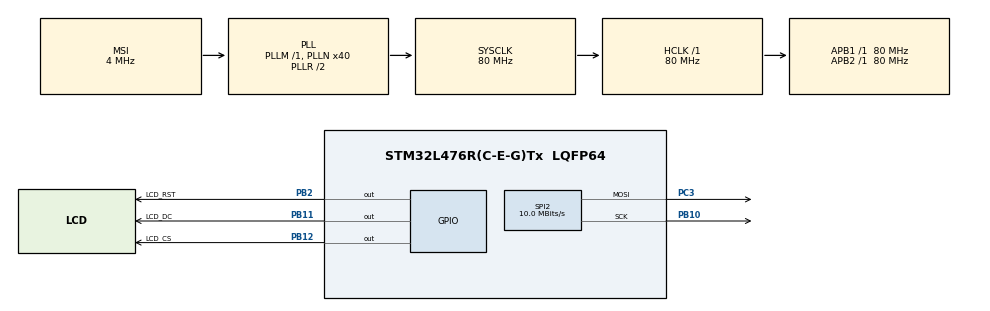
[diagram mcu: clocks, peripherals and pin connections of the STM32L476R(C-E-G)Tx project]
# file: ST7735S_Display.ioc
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Mcu.Family=STM32L4
Mcu.Name=STM32L476R(C-E-G)Tx
Mcu.Package=LQFP64
NVIC.PriorityGroup=NVIC_PRIORITYGROUP_4
PA13\ (JTMS-SWDIO).Mode=Serial_Wire
PA13\ (JTMS-SWDIO).Signal=SYS_JTMS-SWDIO
PA14\ (JTCK-SWCLK).Mode=Serial_Wire
PA14\ (JTCK-SWCLK).Signal=SYS_JTCK-SWCLK
PB10.Mode=TX_Only_Simplex_Unidirect_Master
PB10.Signal=SPI2_SCK
PB11.GPIO_Label=LCD_DC
PB11.Signal=GPIO_Output
PB12.GPIO_Label=LCD_CS
PB12.PinState=GPIO_PIN_SET
PB12.Signal=GPIO_Output
PB2.GPIO_Label=LCD_RST
PB2.Signal=GPIO_Output
PC3.Mode=TX_Only_Simplex_Unidirect_Master
PC3.Signal=SPI2_MOSI
ProjectManager.HeapSize=0x200
ProjectManager.StackSize=0x400
ProjectManager.TargetToolchain=STM32CubeIDE
RCC.AHBFreq_Value=80000000
RCC.APB1Freq_Value=80000000
RCC.APB1TimFreq_Value=80000000
RCC.APB2Freq_Value=80000000
RCC.APB2TimFreq_Value=80000000
RCC.CortexFreq_Value=80000000
RCC.HCLKFreq_Value=80000000
RCC.HSE_VALUE=8000000
RCC.HSI_VALUE=16000000
RCC.LSE_VALUE=32768
RCC.MSI_VALUE=4000000
RCC.PLLN=40
RCC.SYSCLKFreq_VALUE=80000000
RCC.SYSCLKSource=RCC_SYSCLKSOURCE_PLLCLK
RCC.VCOOutputFreq_Value=160000000
SPI2.BaudRatePrescaler=SPI_BAUDRATEPRESCALER_8
SPI2.CalculateBaudRate=10.0 MBits/s
SPI2.DataSize=SPI_DATASIZE_8BIT
SPI2.Direction=SPI_DIRECTION_2LINES
SPI2.Mode=SPI_MODE_MASTER
SPI2.NSSPMode=SPI_NSS_PULSE_DISABLE
SPI2.VirtualType=VM_MASTER
board=custom

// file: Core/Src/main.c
/* USER CODE BEGIN Header */
/**
  ******************************************************************************
  * @file           : main.c
  * @brief          : Main program body
  ******************************************************************************
  * @attention
  *
  * Copyright (c) 2025 STMicroelectronics.
  * All rights reserved.
  *
  * This software is licensed under terms that can be found in the LICENSE file
  * in the root directory of this software component.
  * If no LICENSE file comes with this software, it is provided AS-IS.
  *
  ******************************************************************************
  */
/* USER CODE END Header */
#include "main.h"
#include "spi.h"
#include "gpio.h"

/* USER CODE BEGIN Includes */
#include "display.h"
/* USER CODE END Includes */

void SystemClock_Config(void);

int main(void)
{

  /* MCU Configuration--------------------------------------------------------*/

  /* Reset of all peripherals, Initializes the Flash interface and the Systick. */
  HAL_Init();

  /* Configure the system clock */
  SystemClock_Config();

  /* Initialize all configured peripherals */
  MX_GPIO_Init();
  MX_SPI2_Init();

  /* Infinite loop */
  /* USER CODE BEGIN WHILE */
  displayInit();
  while (1)
  {
    /* USER CODE END WHILE */

  }
}

void SystemClock_Config(void)
{
  RCC_OscInitTypeDef RCC_OscInitStruct = {0};
  RCC_ClkInitTypeDef RCC_ClkInitStruct = {0};

  /** Configure the main internal regulator output voltage
  */
  if (HAL_PWREx_ControlVoltageScaling(PWR_REGULATOR_VOLTAGE_SCALE1) != HAL_OK)
  {
    Error_Handler();
  }

  /** Initializes the RCC Oscillators according to the specified parameters
  * in the RCC_OscInitTypeDef structure.
  */
  RCC_OscInitStruct.OscillatorType = RCC_OSCILLATORTYPE_MSI;
  RCC_OscInitStruct.MSIState = RCC_MSI_ON;
  RCC_OscInitStruct.MSICalibrationValue = 0;
  RCC_OscInitStruct.MSIClockRange = RCC_MSIRANGE_6;
  RCC_OscInitStruct.PLL.PLLState = RCC_PLL_ON;
  RCC_OscInitStruct.PLL.PLLSource = RCC_PLLSOURCE_MSI;
  RCC_OscInitStruct.PLL.PLLM = 1;
  RCC_OscInitStruct.PLL.PLLN = 40;
  RCC_OscInitStruct.PLL.PLLP = RCC_PLLP_DIV7;
  RCC_OscInitStruct.PLL.PLLQ = RCC_PLLQ_DIV2;
  RCC_OscInitStruct.PLL.PLLR = RCC_PLLR_DIV2;
  if (HAL_RCC_OscConfig(&RCC_OscInitStruct) != HAL_OK)
  {
    Error_Handler();
  }

  /** Initializes the CPU, AHB and APB buses clocks
  */
  RCC_ClkInitStruct.ClockType = RCC_CLOCKTYPE_HCLK|RCC_CLOCKTYPE_SYSCLK
                              |RCC_CLOCKTYPE_PCLK1|RCC_CLOCKTYPE_PCLK2;
  RCC_ClkInitStruct.SYSCLKSource = RCC_SYSCLKSOURCE_PLLCLK;
  RCC_ClkInitStruct.AHBCLKDivider = RCC_SYSCLK_DIV1;
  RCC_ClkInitStruct.APB1CLKDivider = RCC_HCLK_DIV1;
  RCC_ClkInitStruct.APB2CLKDivider = RCC_HCLK_DIV1;

  if (HAL_RCC_ClockConfig(&RCC_ClkInitStruct, FLASH_LATENCY_4) != HAL_OK)
  {
    Error_Handler();
  }
}

void Error_Handler(void)
{
  __disable_irq();
  while (1)
  {
  }
}
